# AT32F425 register map
Vendor: Keil; Series: AT32F425; File version: 1.0
CPU: CM4 r0p1, little endian, no MPU, FPU, 4 interrupt priority bits
Registers are 32-bit, read-write, reset 0x0 unless marked. A register's access mark holds for its fields unless they carry their own. Offsets are from the block's base; [hi:lo] are bit positions; {n}, {i} and the like mark numbered series; 'fields as' and 'values as' point back to an identical list.

## TMR16 — General-purpose-timers
Base 0x40014400
Same registers: TMR17 0x40014800
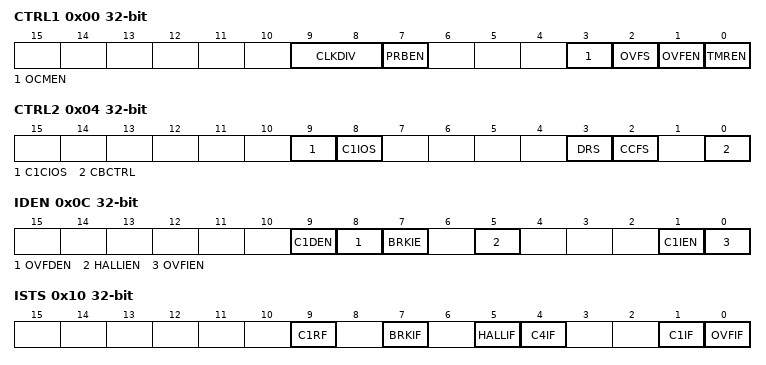
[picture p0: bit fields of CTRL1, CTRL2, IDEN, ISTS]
0x00 CTRL1 — Control register 1
  [9:8] CLKDIV — Clock divider
    0=No division, fDTS=fCK_INT; 1=Div2 (Divided by 2, fDTS=fCK_INT/2); 2=Div4 (Divided by 4, fDTS=fCK_INT/4)
  [7] PRBEN — Period buffer enable
    on read: 0=Disabled (Period buffer is disabled); 1=Enabled (Period buffer is enabled) | on write: 0=Disable (Period buffer disable); 1=Enable (Period buffer enable)
  [3] OCMEN — One cycle mode enable
    0=Continuous (The counter does not stop at an update event); 1=OneCycle (The counter stops at an update event)
  [2] OVFS — Overflow event source
    0=Any (Counter overflow, setting the OVFSWTR bit or overflow event generated by slave timer controller); 1=Counter (Only counter overflow generates an overflow event)
  [1] OVFEN — Overflow event enable
    on read: 0=Enabled (Overflow is enabled); 1=Disabled (Overflow is disabled) | on write: 0=Enable (Overflow enable); 1=Disable (Overflow disable)
  [0] TMREN — TMR enable
    on read: 0=Disabled (Timer is disabled); 1=Enabled (Timer is enabled) | on write: 0=Disable (Timer disable); 1=Enable (Timer enable)
0x04 CTRL2 — Control register 2
  [9] C1CIOS — Channel 1 complementary idle output state
  [8] C1IOS — Channel 1 idle output state
  [3] DRS — DMA request source
    0=Capture/compare event; 1=Overflow event
  [2] CCFS — Channel control bit refresh select
    0=Hall (Control bits are updated by setting the HALL bit); 1=TRGIN (Control bits are updated by setting the HALL bit or a rising edge on TRGIN)
  [0] CBCTRL — Channel buffer control
    on read: 0=Disabled (CxEN, CxCEN and CxOCTRL bits are not buffered); 1=Enabled (CxEN, CxCEN and CxOCTRL bits are buffered) | on write: 0=Disable (CxEN, CxCEN and CxOCTRL bits buffer disable); 1=Enable (CxEN, CxCEN and CxOCTRL bits buffer enable)
0x0C IDEN — Interrupt/DMA enable register
  [n+8] C{n}DEN (n=1..1) — Channel {n} DMA request enable
    on read: 0=Disabled (Channel DMA request is disabled); 1=Enabled (Channel DMA request is enabled) | on write: 0=Disable (Channel DMA request disable); 1=Enable (Channel DMA request enable)
  [8] OVFDEN — Overflow DMA request enable
    on read: 0=Disabled (Overflow event DMA request is disabled); 1=Enabled (Overflow event DMA request is enabled) | on write: 0=Disable (Overflow event DMA request disable); 1=Enable (Overflow event DMA request enable)
  [7] BRKIE — Brake interrupt enable
    on read: 0=Disabled (Break interrupt is disabled); 1=Enabled (Break interrupt is enabled) | on write: 0=Disable (Break interrupt disable); 1=Enable (Break interrupt enable)
  [5] HALLIEN — HALL interrupt enable
    on read: 0=Disabled (HALL interrupt is disabled); 1=Enabled (HALL interrupt is enabled) | on write: 0=Disable (HALL interrupt disable); 1=Enable (HALL interrupt enable)
  [n] C{n}IEN (n=1..1) — Channel {n} interrupt enable
    on read: 0=Disabled (Channel interrupt is disabled); 1=Enabled (Channel interrupt is enabled) | on write: 0=Disable (Channel interrupt disable); 1=Enable (Channel interrupt enable)
  [0] OVFIEN — Overflow interrupt enable
    on read: 0=Disabled (Overflow interrupt is disabled); 1=Enabled (Overflow interrupt is enabled) | on write: 0=Disable (Overflow interrupt disable); 1=Enable (Overflow interrupt enable)
0x10 ISTS — Interrupt status register
  [n+8] C{n}RF (n=1..1) write-0-clears — Channel {n} recapture flag
    on read: 0=NoEvent (No capture is detected); 1=Capture is detected | on write: 0=Clear (Recapture flag clear)
  [7] BRKIF write-0-clears — Brake interrupt flag
    on read: 0=Inactive level; 1=Active level | on write: 0=Clear (Break interrupt flag clear)
  [5] HALLIF write-0-clears — HALL interrupt flag
    on read: 0=NoEvent (No hall event occurs); 1=Hall event is detected | on write: 0=Clear (Hall event flag clear)
  [1] C{x}IF (x=1,4; step 3) write-0-clears — Channel {x} interrupt flag
    on read: 0=NoEvent (No compare event occurs); 1=Capture/Compare event is generated | on write: 0=Clear (Interrupt flag clear)
  [0] OVFIF write-0-clears — Overflow interrupt flag
    on read: 0=No overflow event occurs; 1=Overflow (An overflow event is generated) | on write: 0=Clear (Overflow interrupt flag clear)
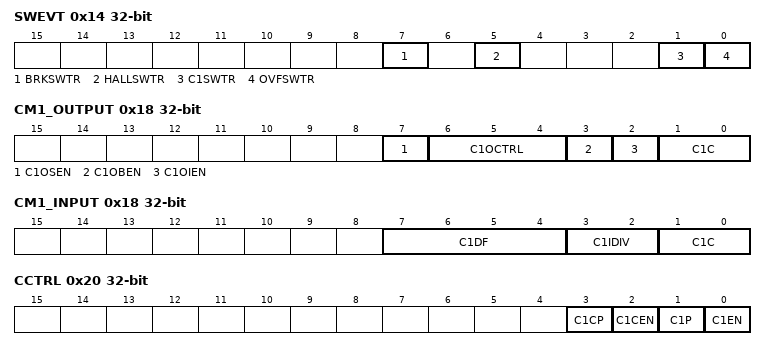
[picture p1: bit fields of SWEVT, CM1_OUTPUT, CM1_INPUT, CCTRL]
0x14 SWEVT — Software event register
  [7] BRKSWTR write-1-sets — Brake event triggered by software
    on write: 1=Event (Generate a break event)
  [5] HALLSWTR write-1-sets — HALL event triggered by software
    on write: 1=Event (Generate a HALL event)
  [n] C{n}SWTR (n=1..1) write-1-sets — Channel {n} event triggered by software
    on write: 1=ChannelEvent (Generate a channel event)
  [0] OVFSWTR write-1-sets — Overflow event triggered by software
    on write: 1=OverflowEvent (Generate an overflow event)
0x18 CM1_OUTPUT — Channel output mode register
  [7] C1OSEN — Channel 1 output switch enable
  [n+5:n+3] C{n}OCTRL (n=1..1) — Channel {n} output control
  [n+2] C{n}OBEN (n=1..1) — Channel {n} output buffer enable
    on read: 0=Disabled (Channel output buffer is disabled); 1=Enabled (Channel output buffer is enabled) | on write: 0=Disable (Channel output buffer disable); 1=Enable (Channel output buffer enable)
  [n+1] C{n}OIEN (n=1..1) — Channel {n} output immediately enable
    0=Compare (Need to compare the CVAL with CxDT before generating an output); 1=Immediately (No need to compare the CVAL and CxDT. An output is generated immediately when a trigger event occurs.)
  [1:0] C1C — Channel 1 configure
0x18 CM1_INPUT (alternate view of CM1_OUTPUT) — Channel input mode register 1
  [n+6:n+3] C{n}DF (n=1..1) — Channel {n} digital filter
  [n+2:n+1] C{n}IDIV (n=1..1) — Channel {n} input divider
    0=Every (No divider. An input capture is generated at each active edge.); 1=Div2 (An input compare is generated every 2 active edges); 2=Div4 (An input compare is generated every 4 active edges); 3=Div8 (An input compare is generated every 8 active edges)
  [1:0] C1C — Channel 1 configure
0x20 CCTRL — Channel control register
  [n+2] C{n}CP (n=1..1) — Channel {n} complementary polarity
    0=High (Output active high or Input active rising edge); 1=Low (Output active low or Input active falling edge)
  [2] C1CEN — Channel 1 complementary enable
  [n] C{n}P (n=1..1) — Channel {n} polarity
    values as C1CP
  [n-1] C{n}EN (n=1..1) — Channel {n} enable
    on read: 0=Disabled (Channel is disabled); 1=Enabled (Channel is enabled) | on write: 0=Disable (Channel disable); 1=Enable (Channel enable)
0x24 CVAL — Counter value
  [15:0] CVAL
0x28 DIV — Divider value
  [15:0] DIV — The counter clock frequency Fck_cnt = Ftmr_clk /({value}+1).
0x2C PR reset 0xFFFF — Period value
  [15:0] PR
0x30 RPR — Repetition of period value
  [7:0] RPR
{0x30+4i} C{i}DT (i=1..1) — Channel {i} data register
  [15:0] C1DT — Channel 1 data register
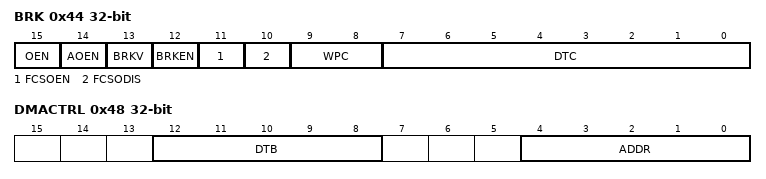
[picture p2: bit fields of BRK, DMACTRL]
0x44 BRK — Brake register
  [15] OEN — Output enable
    on read: 0=Disabled (Output is disabled); 1=Enabled (Output is enabled) | on write: 0=Disable (Output disable); 1=Enable (Output enable)
  [14] AOEN — Automatic output enable
    on read: 0=Disabled (Automatic output is disabled); 1=Enabled (Automatic output is enabled) | on write: 0=Disable (Automatic output disable); 1=Enable (Automatic output enable)
  [13] BRKV — Brake input validity
    0=Low (Break input is active low); 1=High (Break input is active high)
  [12] BRKEN — Brake enable
    on read: 0=Disabled (Break input is disabled); 1=Enabled (Break input is enabled) | on write: 0=Disable (Break input disable); 1=Enable (Break input enable)
  [11] FCSOEN — Frozen channel status when holistic output enable
    on read: 0=Disabled (CxOUT/CxCOUT outputs are disabled); 1=Enabled (CxOUT/CxCOUT outputs are enabled) | on write: 0=Disable (CxOUT/CxCOUT outputs disable); 1=Enable (CxOUT/CxCOUT outputs enable)
  [10] FCSODIS — Frozen channel status when holistic output disable
    values as FCSOEN
  [9:8] WPC — Write protected configuration
    0=NoProtect (Write protection is OFF); 1=Level3 (Write protection level 3, and the following bits are write protected); 2=Level2 (Write protection level 2. The following bits and all bits in level 3 are write protected); 3=Level1 (Write protection level 1. The following bits and all bits in level 2 are write protected)
  [7:0] DTC — Dead-time configuration
0x48 DMACTRL — DMA control register
  [12:8] DTB range 0..17 — DMA transfer bytes
  [4:0] ADDR — DMA transfer address offset
0x4C DMADT — DMA data register
  [15:0] DMADT
